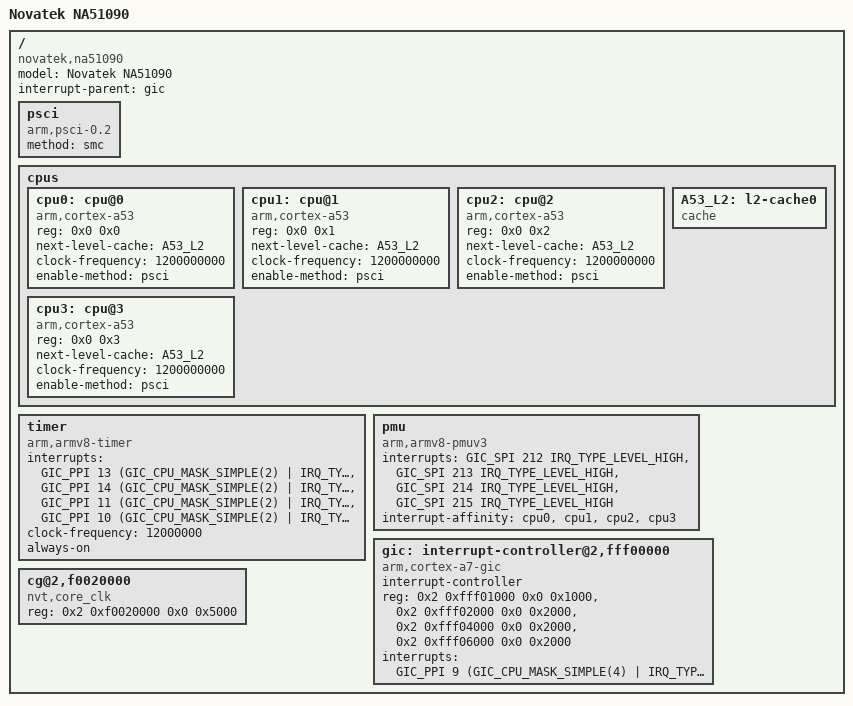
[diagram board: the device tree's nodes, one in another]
/*
 * Novatek Ltd. BSP part of dts
 */

#include <dt-bindings/gpio/gpio.h>
#include <dt-bindings/interrupt-controller/arm-gic.h>

/ {
	model = "Novatek NA51090";
	compatible = "novatek,na51090", "nvt,ca53";
	interrupt-parent = <&gic>;
	#address-cells = <2>;
	#size-cells = <2>;


	psci {
		compatible = "arm,psci-0.2";
		method = "smc";
	};

	cpus {
		#address-cells = <2>;
		#size-cells = <0>;

		cpu0: cpu@0 {
			device_type = "cpu";
			compatible = "arm,cortex-a53", "arm,armv8";
			reg = <0x0 0x0>;
			next-level-cache = <&A53_L2>;
			clock-frequency = <1200000000>;
			enable-method = "psci";
		};
		
		cpu1: cpu@1 {
			device_type = "cpu";
			compatible = "arm,cortex-a53", "arm,armv8";
			reg = <0x0 0x1>;
			next-level-cache = <&A53_L2>;
			clock-frequency = <1200000000>;
			enable-method = "psci";
		};

		cpu2: cpu@2 {
			device_type = "cpu";
			compatible = "arm,cortex-a53", "arm,armv8";
			reg = <0x0 0x2>;
			next-level-cache = <&A53_L2>;
			clock-frequency = <1200000000>;
			enable-method = "psci";
		};

		cpu3: cpu@3 {
			device_type = "cpu";
			compatible = "arm,cortex-a53", "arm,armv8";
			reg = <0x0 0x3>;
			next-level-cache = <&A53_L2>;
			clock-frequency = <1200000000>;
			enable-method = "psci";
		};
		

		A53_L2: l2-cache0 {
			compatible = "cache";
		};
	};

	timer {
		compatible = "arm,armv8-timer";
		interrupts = <GIC_PPI 13 (GIC_CPU_MASK_SIMPLE(2) | IRQ_TYPE_LEVEL_LOW)>,
				<GIC_PPI 14 (GIC_CPU_MASK_SIMPLE(2) | IRQ_TYPE_LEVEL_LOW)>,
				<GIC_PPI 11 (GIC_CPU_MASK_SIMPLE(2) | IRQ_TYPE_LEVEL_LOW)>,
				<GIC_PPI 10 (GIC_CPU_MASK_SIMPLE(2) | IRQ_TYPE_LEVEL_LOW)>;
		clock-frequency = <12000000>; 
		always-on;
	};

	pmu {
		compatible = "arm,armv8-pmuv3";
		interrupts = <GIC_SPI 212 IRQ_TYPE_LEVEL_HIGH>,
				<GIC_SPI 213 IRQ_TYPE_LEVEL_HIGH>,
				<GIC_SPI 214 IRQ_TYPE_LEVEL_HIGH>,
				<GIC_SPI 215 IRQ_TYPE_LEVEL_HIGH>;
		interrupt-affinity = <&cpu0>, <&cpu1>, <&cpu2>, <&cpu3>;
	};

	gic: interrupt-controller@2,fff00000 {
		compatible = "arm,cortex-a7-gic";
		#interrupt-cells = <3>;
		#address-cells = <0>;
		interrupt-controller;
		reg =	<0x2 0xfff01000 0x0 0x1000>,	/* GIC Dist */
			<0x2 0xfff02000 0x0 0x2000>,	/* GIC CPU */
			<0x2 0xfff04000 0x0 0x2000>,    /* GIC VCPU Control */
			<0x2 0xfff06000 0x0 0x2000>;    /* GIC VCPU */
		interrupts = <GIC_PPI 9 (GIC_CPU_MASK_SIMPLE(4) | IRQ_TYPE_LEVEL_HIGH)>;	/* GIC Maintenence IRQ */
	};

	cg@2,f0020000 {
		compatible = "nvt,core_clk";
		reg = <0x2 0xf0020000 0x0 0x5000>;
		reg-names = "cg_rc";
	};

};
